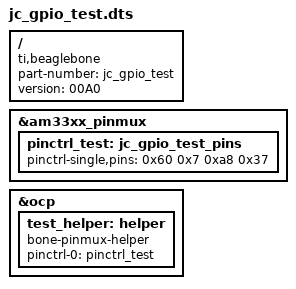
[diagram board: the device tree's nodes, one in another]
/*  
* Copyright (C) 2012 Texas Instruments Incorporated - http://www.ti.com/
*
* This program is free software; you can redistribute it and/or modify
* it under the terms of the GNU General Purpose License Version 2 as
* published by the Free Software Foundation
*
* Original from: github.com/jadonk/validation-scripts/blob/master/test-capemgr/ 
*
* Modified by Derek Molloy for the example on www.derekmolloy.ie
* that maps GPIO pins for the example
*
* Modified by John Comeau for libsoc test that doesn't require additional
* switch and LED components.
*/

/dts-v1/;
/plugin/;

/ {
	compatible = "ti,beaglebone", "ti,beaglebone-black";
	part-number = "jc_gpio_test";
	version = "00A0";

	fragment@0 {
		target = <&am33xx_pinmux>;

		__overlay__ {
			pinctrl_test: jc_gpio_test_pins {
				pinctrl-single,pins = <0x60 0x7 0xa8 0x37>;
			};
		};
	};

	fragment@1 {
		target = <&ocp>;

		__overlay__ {
			test_helper: helper {
				compatible = "bone-pinmux-helper";
				pinctrl-names = "default";
				pinctrl-0 = <&pinctrl_test>;
				status = "okay";
			};
		};
	};
};
